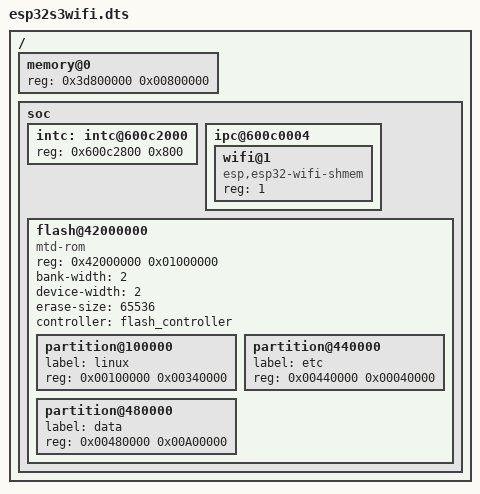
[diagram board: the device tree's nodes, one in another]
// SPDX-License-Identifier: GPL-2.0
/dts-v1/;
/include/ "esp32s3.dtsi"

/ {
	memory@0 {
		device_type = "memory";
		reg = <0x3d800000 0x00800000>;
	};

	soc {
		intc: intc@600c2000 {
			reg = <0x600c2800 0x800>;
		};

		ipc@600c0004 {
			wifi@1 {
				compatible = "esp,esp32-wifi-shmem";
				reg = <1>;
			};
		};

		flash@42000000 {
			#address-cells = <1>;
			#size-cells = <1>;
			compatible = "mtd-rom";
			reg = <0x42000000 0x01000000>;
			bank-width = <2>;
			device-width = <2>;
			erase-size = <65536>;
			controller = <&flash_controller>;
			partition@100000 {
				label = "linux";
				reg = <0x00100000 0x00340000>;
			};
			partition@440000 {
				label = "etc";
				reg = <0x00440000 0x00040000>;
			};
			partition@480000 {
				label = "data";
				reg = <0x00480000 0x00A00000>;
			};
		};
   
	};
};
